# tviic2d6mddr register map
Vendor: Cypress Semiconductor; Series: tviic2d6mddr; File version: 1.0
CPU: CM7 r0p1, little endian, MPU, FPU, VTOR, 3 interrupt priority bits
Registers are 32-bit, read-write, reset 0x0 unless marked. A register's access mark holds for its fields unless they carry their own. Offsets are from the block's base; [hi:lo] are bit positions; lines under a group give offsets from that group; {n}, {i} and the like mark numbered series; 'fields as' and 'values as' point back to an identical list; <NAME> marks a mode.

## SRSS (part 2 of 3) — SRSS Core Registers (ver3p3)
Base 0x40260000
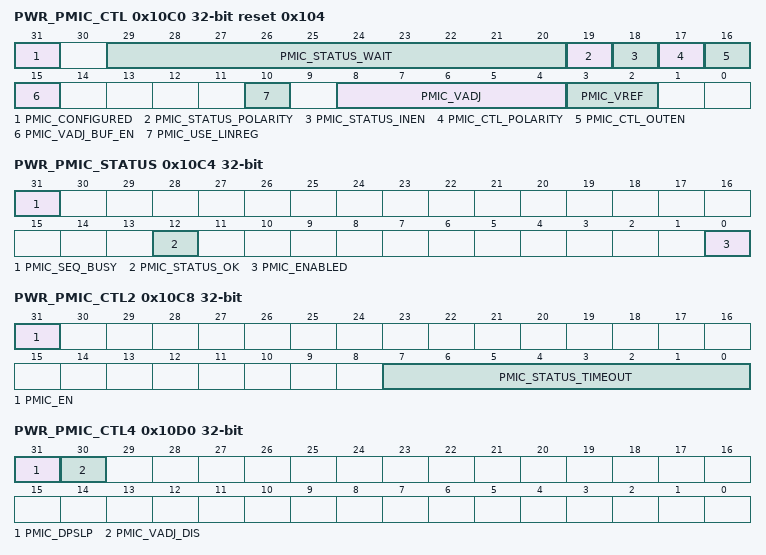
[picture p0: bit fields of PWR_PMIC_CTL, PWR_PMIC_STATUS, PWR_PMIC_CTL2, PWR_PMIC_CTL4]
0x10C0 PWR_PMIC_CTL reset 0x104 — PMIC Control Register
  [31] PMIC_CONFIGURED — Indicates the PMIC has been configured. This is used to know if PMIC should be enabled in response to a debug power up request. Do not change PMIC settings after this bit is set high.
  [29:20] PMIC_STATUS_WAIT — Wait count in 4us steps after PMIC status ok. This is used by the hardware sequencer to allow additional settling time before disabling the internal regulator. The LSB is 32 IMO periods which results in a nominal LSB step of 4us.
  [19] PMIC_STATUS_POLARITY — The polarity used to trigger a reset action based on the PMIC status input. The reset system triggers a reset when the unmasked PMIC status matches this value.
  [18] PMIC_STATUS_INEN — Input buffer enable for PMIC status input. Set this bit high to enable the input receiver.
  [17] PMIC_CTL_POLARITY — Polarity used to enable the PMIC. The sequencer uses PMIC_CTL_POLARITY to enable the PMIC, and it uses the complement to disable the PMIC.
  [16] PMIC_CTL_OUTEN — Output enable for PMIC enable pin. Set this bit high to enable the driver on this pin.
  [15] PMIC_VADJ_BUF_EN — Analog buffer enable on voltage adjust output. Write this bit depending on the type of PMIC connected: 0: Bypass buffer. This connects the resistor divider directly to the output pin. Use this setting for a PMIC with a high-impedance feedback input, such as those that support a resistor divider on the PCB. This setting can also be used with a low-impedance PMIC with PMIC_VREF=2'b11 (no scaling). 1: Use analog buffer. This enables an analog buffer between the resistor divider output and the pin. The buffer can drive a resistor divider on the PCB that feeds into the PMIC feedback input. This allows targeting a different PMIC reference voltage from PMIC_VREF choices, while still supporting voltage adjustment using the internal divider.
  [10] PMIC_USE_LINREG — Controls whether hardware sequencer keeps the internal Active Linear Regulator enabled to improve supply supervision of vccd. When using this feature, if the PMIC fails to keep vccd above the internal regulator target, then the internal regulator will attempt to recover vccd. If the regulator current is too high, the regulator triggers an over-current detector (OCD) reset. 0: Internal Active Linear Regulator disabled after PMIC enabled. OCD is disabled.; 1: Internal Active Linear Regulator kept enabled. See datasheet for minimum PMIC vccd input to prevent OCD.
  [8:4] PMIC_VADJ — Voltage adjustment output setting. The lookup table in this field requires the proper setting in PMIC_VREF for the chosen PMIC. This field has no effect when PMIC_VREF selects no scaling. The feedback tap point is at a vccd pad inside the chip, so the voltage may be a little higher at the PMIC output. Adjust for die to die variation by adding the signed offset value in SFLASH SRSS_PWR_OFFSET.PMIC_VADJ_OFFSET to desired code in this lookup table: 0x03: 1.040V, 0x04: 1.049V, 0x05: 1.057V, 0x06: 1.066V, 0x07: 1.074V, 0x08: 1.083V, 0x09: 1.091V, 0x0A: 1.099V, 0x0B: 1.108V, 0x0C: 1.116V, 0x0D: 1.125V, 0x0E: 1.133V, 0x0F: 1.142V, 0x10: 1.150V, 0x11: 1.158V, 0x12: 1.167V, 0x13: 1.175V, 0x14: 1.184V, 0x15: 1.192V, 0x16: 1.201V, 0x17: 1.209V, 0x18: 1.218V, 0x19: 1.226V, 0x1A: 1.234V, 0x1B: 1.243V, 0x1C: 1.251V, others: Illegal. Behavior is undefined.
  [3:2] PMIC_VREF — PMIC reference voltage setting. This selects the scaling factor used to generate the output voltage (vout) given the feedback voltage (vfb) for the chosen PMIC. For a PMIC that compares vfb to an internal reference voltage (vref) according to the formula vout=vref/vfb, select that vref below. For a PMIC that contains an internal resistor divider and expects an unscaled feedback voltage, use the 'No scaling' choice. 2'b00: Scale for vref=0.9V, use PMIC_VADJ to set the vccd target; 2'b01: Scale for vref=0.8V, use PMIC_VADJ to set the vccd target; 2'b10: Scale for vref=0.6V, use PMIC_VADJ to set the vccd target; 2'b11: No scaling, PMIC_VADJ has no effect
0x10C4 PWR_PMIC_STATUS ro — PMIC Status Register
  [31] PMIC_SEQ_BUSY — Indicates the PMIC enable/disable sequencer is busy transitioning to/from PMIC. 0: Sequencer is not busy; 1: Sequencer is busy either enabling or disabling PMIC.
  [12] PMIC_STATUS_OK — Indicates the PMIC status is ok. This includes polarity adjustment according to PMIC_STATUS_POLARITY. 0: PMIC status is not ok or PMIC input buffer is disabled (PMIC_STATUS_INEN==0); 1: PMIC status input buffer is enabled and indicates ok
  [0] PMIC_ENABLED — Indicates the state of the PMIC enable/disable sequencer. This bit is only valid when PMIC_SEQ_BUSY==0. 0: PMIC sequencer indicates PMIC is disabled. 1: PMIC sequencer indicates PMIC is enabled.
0x10C8 PWR_PMIC_CTL2 — PMIC Control Register 2
  [31] PMIC_EN — Enable PMIC. This bit will not set if PMIC_CONFIGURED==0. Use PWR_PMIC_STATUS.ENABLED to know the actual status of PMIC. It will differ from this bit in the following cases: A) Do not enter DEEPSLEEP while the sequencer is busy (see PWR_PMIC_STATUS.PMIC_SEQ_BUSY). The hardware sequencer disables PMIC during DEEPSLEEP entry and enables it upon wakeup. B) The debugger requests the chip remain powered up. Hardware prevents PMIC from disabling when this bit is cleared. Hardware does not automatically enable PMIC in response to debugger power up request. If this bit is low when the debugger deasserts the power up request, the hardware sequencer will disable PMIC.
  [7:0] PMIC_STATUS_TIMEOUT — Timeout while waiting for PMIC_STATUS_OK==1 when switching to PMIC. 0: disables timeout. Do not change this register after setting PWR_PMIC_CTL.PMIC_CONFIGURED. >0: enables timeout of PMIC_STATUS_TIMEOUT*128us (nominal, clocked by IMO). Timeout expiration generates a 'reset' condition that is only recorded in RES_CAUSE but does not trigger a reset for the SOC, however a WDT will reset the system with PMIC RES_CAUSE.
0x10D0 PWR_PMIC_CTL4 — PMIC Control Register 4
  [31] PMIC_DPSLP — Configures PMIC behavior during DEEPSLEEP. 0: Device operates from internal regulators during DEEPSLEEP. If PMIC is enabled at the beginning of the DEEPSLEEP transition, hardware changes to the internal regulators and disables the PMIC. 1: DEEPSLEEP transition does not change PMIC enable.
  [30] PMIC_VADJ_DIS — Disables the VADJ circuitry. This can be used to decrease current consumption if the entire feedback network is outside the device. 0: Device generates VADJ when PMIC is enabled. This allows the feedback loop to compensate for voltage drops in the PCB and package. 1: Device does not generate VADJ, and it must not be part of the PMIC feedback loop. This reduces current by turning off the internal resistor divider that generates VADJ.
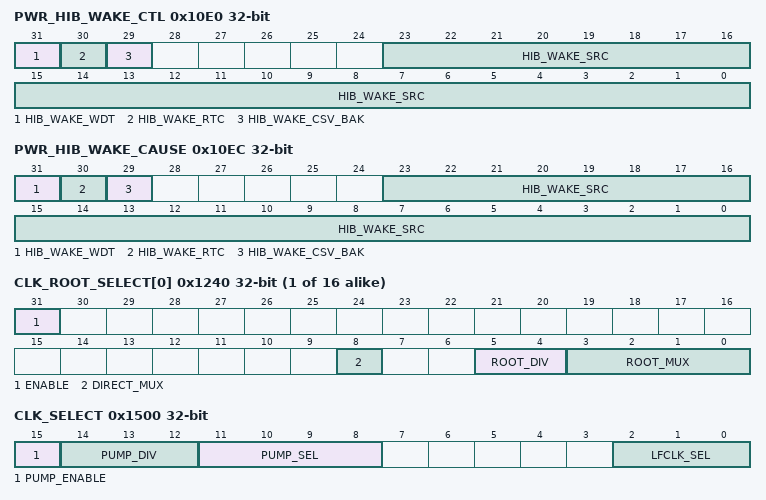
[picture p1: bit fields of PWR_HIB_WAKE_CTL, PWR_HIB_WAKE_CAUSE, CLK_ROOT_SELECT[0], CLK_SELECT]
0x10E0 PWR_HIB_WAKE_CTL — Hibernate Wakeup Mask Register
  [31] HIB_WAKE_WDT — When set, HIBERNATE will wakeup for a pending WDT interrupt.
  [30] HIB_WAKE_RTC — When set, HIBERNATE will wakeup for a pending RTC interrupt.
  [29] HIB_WAKE_CSV_BAK — When set, HIBERNATE will wakeup for CSV_BAK detection.
  [23:0] HIB_WAKE_SRC — When set, HIBERNATE will wakeup for the assigned source The number and assignment of wakeup sources are product-specific.
0x10E4 PWR_HIB_WAKE_CTL2 — Hibernate Wakeup Polarity Register
  [23:0] HIB_WAKE_SRC — Each bit selects the polarity for the corresponding HIBERNATE wakeup source. The number and assignment of wakeup sources are product-specific. 0: Wakes when unmasked input is 0. 1: Wakes when unmasked input is 1.
0x10EC PWR_HIB_WAKE_CAUSE — Hibernate Wakeup Cause Register
  [31] HIB_WAKE_WDT — Indicates WDT wakeup cause. The WDT interrupt must be cleared before this bit can be cleared.
  [30] HIB_WAKE_RTC — Indicates RTC wakeup cause. The RTC interrupt must be cleared before this bit can be cleared.
  [29] HIB_WAKE_CSV_BAK — Indicates CSV_BAK wakeup cause. The related fault must be handled before this bit can be cleared.
  [23:0] HIB_WAKE_SRC — Each bit indicates a HIBERNATE wakeup cause. The number and assigment of wakeup sources are product-specific. For each bit, writing a 1 clears the cause flag.
{0x1200+4i} CLK_PATH_SELECT[{i}] (i=0..15) — Clock Path Select Register
  [2:0] PATH_MUX — Selects a source for clock PATH<i>. Note that not all products support all clock sources. Selecting a clock source that is not supported will result in undefined behavior. It takes four cycles of the originally selected clock to switch away from it. Do not disable the original clock during this time.
    0=IMO (IMO - Internal R/C Oscillator); 1=EXTCLK (EXTCLK - External Clock Pin); 2=ECO (ECO - External-Crystal Oscillator); 3=ALTHF (ALTHF - Alternate High-Frequency clock input (product-specific clock)); 4=DSI_MUX (DSI_MUX - Output of DSI mux for this path. Using a DSI source directly as root of HFCLK will result in undefined behavior.); 5=LPECO (LPECO - Low-Power External-Crystal Oscillator)
{0x1240+4i} CLK_ROOT_SELECT[{i}] (i=0..15) — Clock Root Select Register
  [31] ENABLE — Enable for this clock root. All clock roots default to disabled (ENABLE==0) except HFCLK0, which cannot be disabled.
  [8] DIRECT_MUX — Direct selection mux that allows IMO to bypass most of the clock mux structure. For products with multiple regulators, this mux can be used to reduce current without requiring significant reconfiguration of the clocking network. The default value of HFCLK<0>==ROOT_MUX, and the default value for other clock trees is product-specific.
    0=IMO (Select IMO); 1=ROOT_MUX (Select ROOT_MUX selection)
  [5:4] ROOT_DIV — Selects predivider value for this clock root and DSI input. This divider is after DIRECT_MUX. For products with DSI, the output of this mux is routed to DSI for use as a signal. For products with clock supervision, the output of this mux is the monitored clock for CSV_HF<k>.
    0=NO_DIV (Transparent mode, feed through selected clock source w/o dividing.); 1=DIV_BY_2 (Divide selected clock source by 2); 2=DIV_BY_4 (Divide selected clock source by 4); 3=DIV_BY_8 (Divide selected clock source by 8)
  [3:0] ROOT_MUX — Selects a clock path as the root of HFCLK<k> and for SRSS DSI input <k>. Use CLK_PATH_SELECT[i] to configure the desired path. Some paths may have FLL or PLL available (product-specific), and the control and bypass mux selections of these are in other registers. Configure the FLL using CLK_FLL_CONFIG register. Configure a PLL using the related CLK_PLL_CONFIG[k] register. Note that not all products support all clock sources. Selecting a clock source that is not supported will result in undefined behavior. It takes four cycles of the originally selected clock to switch away from it. Do not disable the original clock during this time.
    0=PATH0 (Select PATH0 (can be configured for FLL)); {v}=PATH{v} (Select PATH{v} (can be configured for PLL{v-1}, if available in the product)) (v=1..15)
0x1400 CSV_HF group — Clock Supervisor (CSV) registers for Root clocks
  {0x0+0x10*j} CSV[{j}] (j=0..15) group — Active domain Clock Supervisor (CSV) registers
    0x00 REF_CTL — Clock Supervision Reference Control
      [31] CSV_EN — Enables clock supervision, both frequency and loss. CSV in Active domain: Clock supervision is reset during DeepSleep and Hibernate modes. When enabled it begins operating automatically after a DeepSleep wakeup, but it must be reconfigured after Hibernate wakeup. CSV in DeepSleep domain: Clock supervision is reset during Hibernate mode. It must be reconfigured after Hibernate wakeup. A CSV error detection is reported to the Fault structure, or instead it can generate a power reset.
      [30] CSV_ACTION — Specifies the action taken when an anomaly is detected on the monitored clock. CSV in DeepSleep domain always do a Fault report (which also wakes up the system).
        0=FAULT (Do a Fault report.); 1=RESET (Cause a power reset. This should only be used for clk_hf0.)
      [15:0] STARTUP — Startup delay time -1 (in reference clock cycles), after enable or DeepSleep wakeup, from reference clock start to monitored clock start. At a minimum (both clocks running): STARTUP >= (PERIOD +3) * FREQ_RATIO - UPPER, with FREQ_RATIO = (Reference frequency / Monitored frequency) On top of that the actual clock startup delay and the margin for accuracy of both clocks must be added.
    0x04 REF_LIMIT — Clock Supervision Reference Limits
      [31:16] UPPER — Cycle time upper limit. Set the upper limit -1, in reference clock cycles, before (or same time) the next monitored clock event must happen. If a monitored clock event does not happen before this limit is reached, or does not happen at all (clock loss), a CSV error is detected.
      [15:0] LOWER — Cycle time lower limit. Set the lower limit -1, in reference clock cycles, before the next monitored clock event is allowed to happen. If a monitored clock event happens before this limit is reached a CSV error is detected. LOWER must be at least 1 less than UPPER. In case the clocks are asynchronous LOWER must be at least 3 less than UPPER.
    0x08 MON_CTL — Clock Supervision Monitor Control
      [15:0] PERIOD — Period time. Set the Period -1, in monitored clock cycles, before the next monitored clock event happens. PERIOD <= (UPPER+1) / FREQ_RATIO -1, with FREQ_RATIO = (Reference frequency / Monitored frequency) In case the clocks are asynchronous: PERIOD <= UPPER / FREQ_RATIO -1 Additionally margin must be added for accuracy of both clocks.
0x1500 CLK_SELECT — Clock selection register
  [15] PUMP_ENABLE
  [14:12] PUMP_DIV
    0=NO_DIV (N/A); 1=DIV_BY_2 (N/A); 2=DIV_BY_4 (N/A); 3=DIV_BY_8 (N/A); 4=DIV_BY_16 (N/A)
  [11:8] PUMP_SEL
  [2:0] LFCLK_SEL — Select source for LFCLK. Note that not all products support all clock sources. Selecting a clock source that is not supported will result in undefined behavior. Writes to this field are ignored unless the WDT is unlocked using WDT_LOCK register. It takes four cycles of the originally selected clock to switch away from it. Do not disable the original clock during this time.
    0=ILO0 (ILO0 - Internal Low-speed Oscillator #0.); 1=WCO (WCO - Watch-Crystal Oscillator. Requires Backup domain to be present and properly configured (including external watch crystal, if used).); 2=ALTLF (ALTLF - Alternate Low-Frequency Clock. Capability is product-specific); 3=PILO (PILO - Precision ILO. If present, it works in DEEPSLEEP and higher modes. Does not work in HIBERNATE mode.); 4=ILO1 (ILO1 - Internal Low-speed Oscillator #1, if present.); 5=ECO_PRESCALER (ECO_PRESCALER - External-Crystal Oscillator after prescaling, if present. Does not work in DEEPSLEEP or HIBERNATE modes. Intended for applications that operate in ACTIVE/SLEEP modes only. This option is only valid when ECO is present in the product.); 6=LPECO_PRESCALER (LPECO_PRESCALER - Low-Power External-Crystal Oscillator after prescaling, if present. This choice works in ACTIVE/SLEEP/DEEPSLEEP modes. This option is only valid when LPECO is present in the product.)
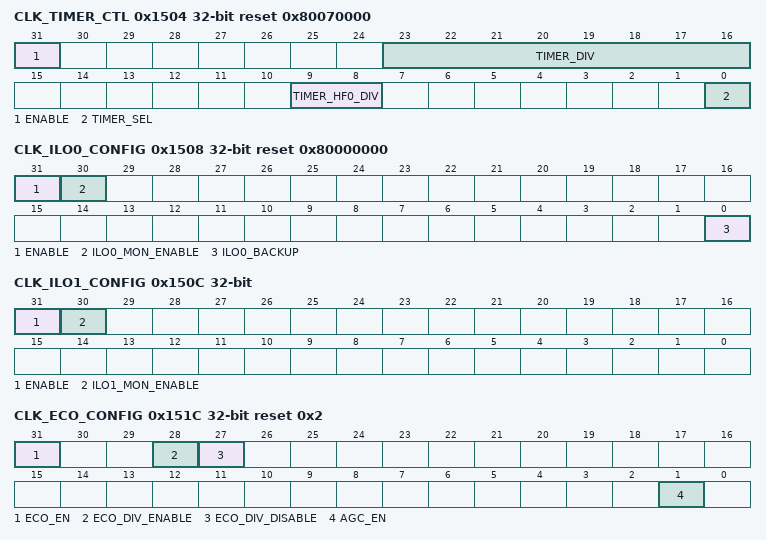
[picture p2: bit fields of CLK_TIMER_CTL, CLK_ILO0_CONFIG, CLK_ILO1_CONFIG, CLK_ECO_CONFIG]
0x1504 CLK_TIMER_CTL reset 0x80070000 — Timer Clock Control Register
  [31] ENABLE — Obsolete. Do not use in new designs. Keep default value in new designs.
  [23:16] TIMER_DIV — Obsolete. Do not use in new designs. Keep default value in new designs.
  [9:8] TIMER_HF0_DIV — Obsolete. Do not use in new designs. Keep default value in new designs.
    0=NO_DIV (Obsolete. Do not use in new designs. Keep default value in new designs.); 1=DIV_BY_2 (Obsolete. Do not use in new designs.); 2=DIV_BY_4 (Obsolete. Do not use in new designs.); 3=DIV_BY_8 (Obsolete. Do not use in new designs.)
  [0] TIMER_SEL — Obsolete. Do not use in new designs. Keep default value in new designs.
    0=IMO (Obsolete. Do not use in new designs. Keep default value in new designs.); 1=HF0_DIV (Obsolete. Do not use in new designs.)
0x1508 CLK_ILO0_CONFIG reset 0x80000000 — ILO0 Configuration
  [31] ENABLE — Master enable for ILO. Writes to this field are ignored unless the WDT is unlocked using WDT_LOCK register. HT-variant: This register will not clear unless PWR_CTL2.BGREF_LPMODE==0. After enabling, the first ILO0 cycle occurs within 12us and is +/-10 percent accuracy. Thereafter, ILO0 is +/-5 percent accurate.
  [30] ILO0_MON_ENABLE
  [0] ILO0_BACKUP — This register indicates that ILO0 should stay enabled during XRES and HIBERNATE modes. If backup voltage domain is implemented on the product, this bit also indicates if ILO0 should stay enabled through power-related resets on other supplies, e.g.. BOD on VDDD/VCCD. Writes to this field are ignored unless the WDT is unlocked using WDT_LOCK register. This register is reset when the backup logic resets. 0: ILO0 turns off during XRES, HIBERNATE, and power-related resets. ILO0 configuration and trims are reset by these events. 1: ILO0 stays enabled, as described above. ILO0 configuration and trims are not reset by these events.
0x150C CLK_ILO1_CONFIG — ILO1 Configuration
  [31] ENABLE — Master enable for ILO1. HT-variant: After enabling, the first ILO1 cycle occurs within 12us and is +/-10 percent accuracy. Thereafter, ILO1 is +/-5 percent accurate.
  [30] ILO1_MON_ENABLE
0x1518 CLK_IMO_CONFIG reset 0x80000000 — IMO Configuration
  [31] ENABLE — Master enable for IMO oscillator. This bit must be high at all times for all functions to work properly. Hardware will automatically disable the IMO during DEEPSLEEP, HIBERNATE, and XRES.
0x151C CLK_ECO_CONFIG reset 0x2 — ECO Configuration Register
  [31] ECO_EN — Master enable for ECO oscillator. Configure the settings in CLK_ECO_CONFIG2 to work with the selected crystal, before enabling ECO.
  [28] ECO_DIV_ENABLE — ECO prescaler enable command (mutually exclusive with ECO_DIV_DISABLE). ECO Prescaler only works in ACTIVE and SLEEP modes. SW sets this field to '1' to enable the divider and HW sets this field to '0' to indicate that divider enabling has completed. When the divider is enabled, its integer and fractional counters are initialized to '0'. If a divider is to be re-enabled using different integer and fractional divider values, the SW should follow these steps: 0: Disable the divider using the ECO_DIV_DISABLE field. 1: Configure CLK_ECO_PRESCALE registers. 2: Enable the divider using the ECO_DIV_ENABLE field. HW sets the ECO_DIV_ENABLE field to '0' when the enabling is performed and HW set CLK_ECO_PRESCALER.ENABLED to '1' when the enabling is performed.
  [27] ECO_DIV_DISABLE — ECO prescaler disable command (mutually exclusive with ECO_DIV_ENABLE). SW sets this field to '1' and HW sets this field to '0'. HW sets ECO_DIV_DISABLE field to '0' immediately and HW sets CLK_ECO_PRESCALE.ECO_DIV_EN field to '0' immediately.
  [1] AGC_EN — Automatic Gain Control (AGC) enable. When set, the oscillation amplitude is controlled to the level selected by CLK_ECO_CONFIG2.ATRIM. When low, the amplitude is not explicitly controlled and can be as high as the vddd supply. WARNING: use care when disabling AGC because driving a crystal beyond its rated limit can permanently damage the crystal.
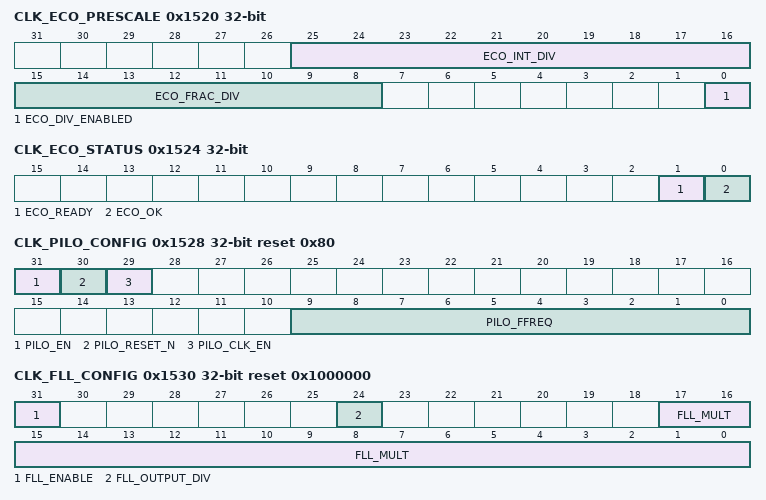
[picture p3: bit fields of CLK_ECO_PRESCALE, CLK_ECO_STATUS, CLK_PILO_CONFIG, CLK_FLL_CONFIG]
0x1520 CLK_ECO_PRESCALE — ECO Prescaler Configuration Register
  [25:16] ECO_INT_DIV — 10-bit integer value allows for ECO frequencies up to 33.55MHz. Subtract one from the desired divide value when writing this field. For example, to divide by 1, write ECO_INT_DIV=0. Do not change this setting when ECO Prescaler is enabled.
  [15:8] ECO_FRAC_DIV — 8-bit fractional value, sufficient to get prescaler output within the +/-65ppm calibration range. Do not change this setting when ECO Prescaler is enabled.
  [0] ECO_DIV_ENABLED ro — ECO prescaler enabled. HW sets this field to '1' as a result of an CLK_ECO_CONFIG.ECO_DIV_ENABLE command. HW sets this field to '0' as a result on a CLK_ECO_CONFIG.ECO_DIV_DISABLE command.
0x1524 CLK_ECO_STATUS ro — ECO Status Register
  [1] ECO_READY — Indicates the ECO internal oscillator circuit has had enough time to fully stabilize. This is the output of a counter since ECO was enabled, and it does not check the ECO output. It is recommended to also confirm ECO_OK==1.
  [0] ECO_OK — Indicates the ECO internal oscillator circuit has sufficient amplitude. It may not meet the PPM accuracy or duty cycle spec.
0x1528 CLK_PILO_CONFIG reset 0x80 — Precision ILO Configuration Register
  [31] PILO_EN — Enable PILO. When enabling PILO, set PILO_EN=1, wait 1ms, then PILO_RESET_N=1 and PILO_CLK_EN=1. When disabling PILO, clear PILO_EN=0, PILO_RESET_N=0, and PLO_CLK_EN=0 in the same write cycle.
  [30] PILO_RESET_N — Reset the PILO. See PILO_EN field for required sequencing.
  [29] PILO_CLK_EN — Enable the PILO clock output. See PILO_EN field for required sequencing.
  [9:0] PILO_FFREQ — Fine frequency trim allowing +/-250ppm accuracy with periodic calibration. The nominal step size of the LSB is 8Hz.
0x1530 CLK_FLL_CONFIG reset 0x1000000 — FLL Configuration Register
  [31] FLL_ENABLE — Master enable for FLL. The FLL requires firmware sequencing when enabling and disabling. Hardware handles sequencing automatically when entering/exiting DEEPSLEEP. To enable the FLL, use the following sequence: 1) Configure FLL and CCO settings. Do not modify CLK_FLL_CONFIG3.BYPASS_SEL (must be AUTO) or CLK_FLL_CONFIG.FLL_ENABLE (must be 0). 2) Enable the CCO by writing CLK_FLL_CONFIG4.CCO_ENABLE=1 3) Wait until CLK_FLL_STATUS.CCO_READY==1. 4) Ensure the reference clock has stabilized. 5) Write FLL_ENABLE=1. 6) Optionally wait until CLK_FLL_STATUS.LOCKED==1. The hardware automatically changes to the FLL output when LOCKED==1. To disable the FLL, use the following sequence: 1) Write CLK_FLL_CONFIG3.BYPASS_SEL=FLL_REF. 2) Read CLK_FLL_CONFIG3.BYPASS_SEL to ensure the write completes (read is not optional). 3) Wait at least ten cycles of either FLL reference clock or FLL output clock, whichever is slower. It is recommended to use a HW counter (e.g. clock calibration counter, event generator) running on the slower clock. 4) Disable FLL with FLL_ENABLE=0. 5) Disable the CCO by writing CLK_FLL_CONFIG4.CCO_ENABLE=0. 6) Write CLK_FLL_CONFIG3.BYPASS_SEL=AUTO. 7) Read CLK_FLL_CONFIG3.BYPASS_SEL to ensure the write completes (read is not optional). 8) Wait three cycles of FLL reference clock. It is recommended to use a HW counter (e.g. clock calibration counter, event generator) running on the reference clock. 0: Block is powered off 1: Block is powered on
  [24] FLL_OUTPUT_DIV — Control bits for Output divider. Set the divide value before enabling the FLL, and do not change it while FLL is enabled. 0: no division 1: divide by 2
  [17:0] FLL_MULT — Multiplier to determine CCO frequency in multiples of the frequency of the selected reference clock (Fref). Ffll = (FLL_MULT) * (Fref / REFERENCE_DIV) / (OUTPUT_DIV+1)
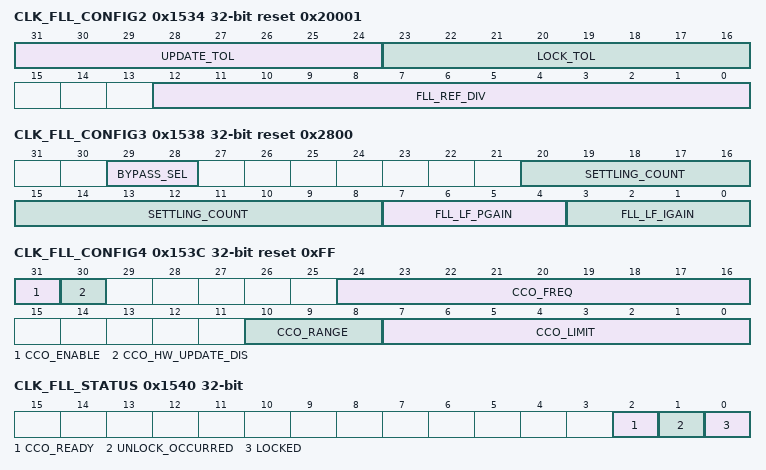
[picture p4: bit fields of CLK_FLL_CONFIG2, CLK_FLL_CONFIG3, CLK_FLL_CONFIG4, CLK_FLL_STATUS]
0x1534 CLK_FLL_CONFIG2 reset 0x20001 — FLL Configuration Register 2
  [31:24] UPDATE_TOL — Update tolerance sets the error threshold for when the FLL will update the CCO frequency settings. The update tolerance is the allowed difference between the count value for the ideal formula and the measured value. UPDATE_TOL should be less than LOCK_TOL.
  [23:16] LOCK_TOL — Lock tolerance sets the error threshold for when the FLL output is considered locked to the reference input. A high tolerance can be used to lock more quickly or allow less accuracy. The tolerance is the allowed difference between the count value for the ideal formula and the measured value. 0: tolerate error of 1 count value 1: tolerate error of 2 count values ... 255: tolerate error of 256 count values
  [12:0] FLL_REF_DIV — Control bits for reference divider. Set the divide value before enabling the FLL, and do not change it while FLL is enabled. 0: illegal (undefined behavior) 1: divide by 1 ... 8191: divide by 8191
0x1538 CLK_FLL_CONFIG3 reset 0x2800 — FLL Configuration Register 3
  [29:28] BYPASS_SEL — Bypass mux located just after FLL output. This register can be written while the FLL is enabled. When changing BYPASS_SEL, do not turn off the reference clock or CCO clock for five cycles (whichever is slower). In case of disabling FLL(FLL_ENABLE=0), additional five cycles are required. Refer to FLL disable sequence for more details in CLK_FLL_CONFIG->FLL_ENABLE. Whenever BYPASS_SEL is changed, it is required to read CLK_FLL_CONFIG3 to ensure the change takes effect.
    0=AUTO (Automatic using lock indicator. When unlocked, automatically selects FLL reference input (bypass mode). When locked, automatically selects FLL output. This can allow some processing to occur while the FLL is locking, such as after DEEPSLEEP wakeup. It is incompatible with clock supervision, because the frequency changes based on the lock signal.); 1=LOCKED_OR_NOTHING (Similar to AUTO, except the clock is gated off when unlocked. This is compatible with clock supervision, because the supervisors allow no clock during startup (until a timeout occurs), and the clock targets the proper frequency whenever it is running.); 2=FLL_REF (Select FLL reference input (bypass mode). Ignores lock indicator); 3=FLL_OUT (Select FLL output. Ignores lock indicator.)
  [20:8] SETTLING_COUNT — Number of undivided reference clock cycles to wait after changing the CCO trim until the loop measurement restarts. A delay allows the CCO output to settle and gives a more accurate measurement. The default is tuned to an 8MHz reference clock since the IMO is expected to be the most common use case. 0: no settling time 1: wait one reference clock cycle ... 8191: wait 8191 reference clock cycles
  [7:4] FLL_LF_PGAIN — FLL Loop Filter Gain Setting #2. The proportional gain is the sum of FLL_LF_IGAIN and FLL_LF_PGAIN. 0: 1/256 1: 1/128 2: 1/64 3: 1/32 4: 1/16 5: 1/8 6: 1/4 7: 1/2 8: 1.0 9: 2.0 10: 4.0 11: 8.0 >=12: illegal
  [3:0] FLL_LF_IGAIN — FLL Loop Filter Gain Setting #1. The proportional gain is the sum of FLL_LF_IGAIN and FLL_LF_PGAIN. 0: 1/256 1: 1/128 2: 1/64 3: 1/32 4: 1/16 5: 1/8 6: 1/4 7: 1/2 8: 1.0 9: 2.0 10: 4.0 11: 8.0 >=12: illegal
0x153C CLK_FLL_CONFIG4 reset 0xFF — FLL Configuration Register 4
  [31] CCO_ENABLE — Enable the CCO. It is required to enable the CCO before using the FLL. 0: Block is powered off 1: Block is powered on
  [30] CCO_HW_UPDATE_DIS — Disable CCO frequency update by FLL hardware 0: Hardware update of CCO settings is allowed. Use this setting for normal FLL operation. 1: Hardware update of CCO settings is disabled. Use this setting for open-loop FLL operation.
  [24:16] CCO_FREQ — CCO frequency code. This is updated by HW when the FLL is enabled. It can be manually updated to use the CCO in an open loop configuration. The meaning of each frequency code depends on the range.
  [10:8] CCO_RANGE — Frequency range of CCO
    0=RANGE0 (Target frequency is in range [48, 64) MHz); 1=RANGE1 (Target frequency is in range [64, 85) MHz); 2=RANGE2 (Target frequency is in range [85, 113) MHz); 3=RANGE3 (Target frequency is in range [113, 150) MHz); 4=RANGE4 (Target frequency is in range [150, 200] MHz)
  [7:0] CCO_LIMIT — Maximum CCO offset allowed (used to prevent FLL dynamics from selecting an CCO frequency that the logic cannot support)
0x1540 CLK_FLL_STATUS — FLL Status Register
  [2] CCO_READY ro — This indicates that the CCO is internally settled and ready to use.
  [1] UNLOCK_OCCURRED — This bit sets whenever the FLL is enabled and goes out of lock. This bit stays set until cleared by firmware.
  [0] LOCKED ro — FLL Lock Indicator
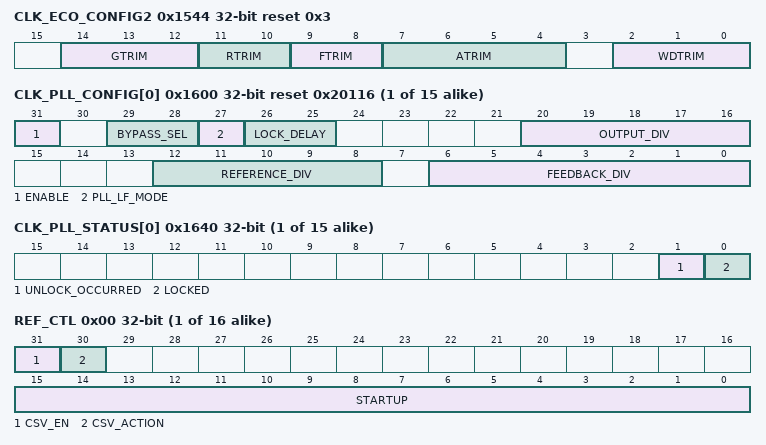
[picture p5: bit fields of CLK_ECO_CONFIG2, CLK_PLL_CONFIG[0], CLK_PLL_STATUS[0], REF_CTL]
0x1544 CLK_ECO_CONFIG2 reset 0x3 — ECO Configuration Register 2
  [14:12] GTRIM — Gain Trim - Startup time.
  [11:10] RTRIM — Feedback resistor Trim
  [9:8] FTRIM — Filter Trim - 3rd harmonic oscillation
  [7:4] ATRIM — Amplitude trim. Sets maximum oscillation amplitude (Vp) to set the crystal drive level when ECO_CONFIG.AGC_EN=1. When AGC_EN=0, most values of this register are unused, except as noted. WARNING: use care when setting this field because driving a crystal beyond its rated limit can permanently damage the crystal. 0x0: Vp < 0.35V 0x1: Vp < 0.40V 0x2: Vp < 0.45V 0x3: Vp < 0.50V 0x4: Vp < 0.55V 0x5: Vp < 0.60V 0x6: Vp < 0.65V 0x7: Vp < 0.70V 0x8: Vp < 0.75V 0x9: Vp < 0.80V 0xA: Vp < 0.85V 0xB: Vp < 0.90V 0xC: Vp < 0.95V 0xD: Vp < 1.00V 0xE: Vp < 1.05V 0xF: Vp < 1.10V when AGC_EN=1. When AGC_EN=0, this setting enables maximum swing between vddd and vssd.
  [2:0] WDTRIM — Watch Dog Trim. Sets the minimum oscillation amplitude (Vp) for the crystal drive level. The minimum amplitude detector output is readable in CLK_ECO_STATUS.ECO_OK. 0x0: Vp > 0.05V 0x1: Vp > 0.10V 0x2: Vp > 0.15V 0x3: Vp > 0.20V 0x4: Vp > 0.25V 0x5: Vp > 0.30V 0x6: Vp > 0.35V 0x7: Vp > 0.40V
{0x1600+4i} CLK_PLL_CONFIG[{i}] (i=0..14) reset 0x20116 — PLL Configuration Register
  [31] ENABLE — Master enable for PLL. Setup FEEDBACK_DIV, REFERENCE_DIV, and OUTPUT_DIV at least one cycle before setting ENABLE=1. Fpll = (FEEDBACK_DIV) * (Fref / REFERENCE_DIV) / (OUTPUT_DIV) 0: Block is disabled. When the PLL disables, hardware controls the bypass mux as described in BYPASS_SEL, before disabling the PLL circuit. 1: Block is enabled
  [29:28] BYPASS_SEL — Bypass mux located just after PLL output. This selection is glitch-free and can be changed while the PLL is running. When changing BYPASS_SEL, do not turn off the reference clock or PLL clock for five cycles (whichever is slower).
    0=AUTO (Automatic using lock indicator. When unlocked, automatically selects PLL reference input (bypass mode). When locked, automatically selects PLL output. If ENABLE=0, automatically selects PLL reference input.); 1=LOCKED_OR_NOTHING (Similar to AUTO, except the clock is gated off when unlocked. This is compatible with clock supervision, because the supervisors allow no clock during startup (until a timeout occurs), and the clock targets the proper frequency whenever it is running. If ENABLE=0, no clock is output.); 2=PLL_REF (Select PLL reference input (bypass mode). Ignores lock indicator); 3=PLL_OUT (Select PLL output. Ignores lock indicator. If ENABLE=0, no clock is output.)
  [27] PLL_LF_MODE — VCO frequency range selection. Configure this bit according to the targeted VCO frequency. Do not change this setting while the PLL is enabled. 0: VCO frequency is [200MHz, 400MHz] 1: VCO frequency is [170MHz, 200MHz)
  [26:25] LOCK_DELAY
  [20:16] OUTPUT_DIV — Control bits for Output divider. Set the divide value before enabling the PLL, and do not change it while PLL is enabled. 0: illegal (undefined behavior) 1: illegal (undefined behavior) 2: divide by 2. Suitable for direct usage as HFCLK source. ... 16: divide by 16. Suitable for direct usage as HFCLK source. >16: illegal (undefined behavior)
  [12:8] REFERENCE_DIV — Control bits for reference divider. Set the divide value before enabling the PLL, and do not change it while PLL is enabled. 0: illegal (undefined behavior) 1: divide by 1 ... 20: divide by 20 others: illegal (undefined behavior)
  [6:0] FEEDBACK_DIV — Control bits for feedback divider. Set the divide value before enabling the PLL, and do not change it while PLL is enabled. 0-21: illegal (undefined behavior) 22: divide by 22 ... 112: divide by 112 >112: illegal (undefined behavior)
{0x1640+4i} CLK_PLL_STATUS[{i}] (i=0..14) — PLL Status Register
  [1] UNLOCK_OCCURRED — This bit sets whenever the PLL Lock bit goes low, and stays set until cleared by firmware.
  [0] LOCKED ro — PLL Lock Indicator
0x1700 CSV_REF_SEL — Select CSV Reference clock for Active domain
  [2:0] REF_MUX — Selects a source for clock clk_ref_hf. Note that not all products support all clock sources. Selecting a clock source that is not supported will result in undefined behavior. It takes four cycles of the originally selected clock to switch away from it. Do not disable the original clock during this time.
    0=IMO (IMO - Internal R/C Oscillator); 1=EXTCLK (EXTCLK - External Clock Pin); 2=ECO (ECO - External-Crystal Oscillator); 3=ALTHF (ALTHF - Alternate High-Frequency clock input (product-specific clock))
0x1710 CSV_REF group — CSV registers for the CSV Reference clock
  0x00 CSV group — Active domain Clock Supervisor (CSV) registers for CSV Reference clock
    0x00 REF_CTL — Clock Supervision Reference Control
      fields as CSV_HF.CSV[0].REF_CTL
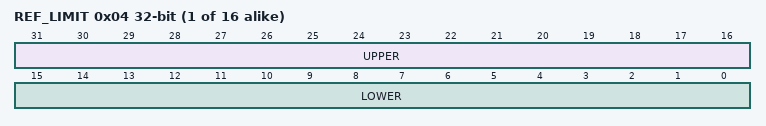
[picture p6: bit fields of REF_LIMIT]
    0x04 REF_LIMIT — Clock Supervision Reference Limits
      fields as CSV_HF.CSV[0].REF_LIMIT
    0x08 MON_CTL — Clock Supervision Monitor Control
      fields as CSV_HF.CSV[0].MON_CTL
0x1720 CSV_LF group — CSV registers for LF clock
  0x00 CSV group — LF clock Clock Supervisor registers
    0x00 REF_CTL — Clock Supervision Reference Control
      [31] CSV_EN — Enables clock supervision, both frequency and loss. CSV in Active domain: Clock supervision is reset during DeepSleep and Hibernate modes. When enabled it begins operating automatically after a DeepSleep wakeup, but it must be reconfigured after Hibernate wakeup. CSV in DeepSleep domain: Clock supervision is reset during Hibernate mode. It must be reconfigured after Hibernate wakeup. CSV in Backup domain: Clock supervision operates during Hibernate mode, can be configured to wake from Hibernate, and continues operating during reboot. A CSV error detection is reported to the Fault structure.
      [8:0] STARTUP — Startup delay time -1 (in reference clock cycles), after enable, from reference clock start to monitored clock start. At a minimum (both clocks running): STARTUP >= (PERIOD +3) * FREQ_RATIO - UPPER, with FREQ_RATIO = (Reference frequency / Monitored frequency) On top of that the actual clock startup delay and the margin for accuracy of both clocks must be added.
    0x04 REF_LIMIT — Clock Supervision Reference Limits
      [23:16] UPPER — Cycle time upper limit. Set the upper limit -1, in reference clock cycles, before (or same time) the next monitored clock event must happen. If a monitored clock event does not happen before this limit is reached, or does not happen at all (clock loss), a CSV error is detected.
      [7:0] LOWER — Cycle time lower limit. Set the lower limit -1, in reference clock cycles, before the next monitored clock event is allowed to happen. If a monitored clock event happens before this limit is reached a CSV error is detected. LOWER must be at least 1 less than UPPER. In case the clocks are asynchronous LOWER must be at least 3 less than UPPER.
    0x08 MON_CTL — Clock Supervision Monitor Control
      [7:0] PERIOD — Period time. Set the Period -1, in monitored clock cycles, before the next monitored clock event happens. PERIOD <= (UPPER+1) / FREQ_RATIO -1, with FREQ_RATIO = (Reference frequency / Monitored frequency) In case the clocks are asynchronous: PERIOD <= UPPER / FREQ_RATIO -1 Additionally margin must be added for accuracy of both clocks.
0x1730 CSV_ILO group — CSV registers for HVILO clock
  0x00 CSV group — ILO0 clock DeepSleep domain Clock Supervisor registers
    0x00 REF_CTL — Clock Supervision Reference Control
      fields as CSV_LF.CSV.REF_CTL
    0x04 REF_LIMIT — Clock Supervision Reference Limits
      fields as CSV_LF.CSV.REF_LIMIT
    0x08 MON_CTL — Clock Supervision Monitor Control
      fields as CSV_LF.CSV.MON_CTL
